# BlueNRG1 register map
Vendor: STMicroelectronics; Series: BlueNRG1; File version: 2.2.1
CPU: CM0 r0p0, little endian, no MPU, no FPU, 2 interrupt priority bits
Registers are 32-bit, read-write, reset 0x0 unless marked. A register's access mark holds for its fields unless they carry their own. Offsets are from the block's base; [hi:lo] are bit positions; 'fields as' and 'values as' point back to an identical list; <NAME> marks a mode.

## MFT1
Base 0x40D00000
Same registers: MFT2 0x40E00000
0x00 TNCNT1 16-bit — The Timer/Counter 1 register is a 16-bit RW register that is not altered by reset and thus contains random data upon power-up. Reading the register returns the current value of the Timer/Counter 1. TnCNT1 can only be written by the software when MFT is enabled (TnEN = 1). When MFT is disabled (TnEN = 0), write operations on TnCNT1 register are ignored.
0x04 TNCRA 16-bit — The Capture/Reload A register is a 16-bit RW register that is not affected by reset and thus contains random data upon power-up. The software may read the register at any time. However, the register can only be written by the software when MFT is enabled (TnEN = 1). When MFT is disabled (TnEN = 0), write operations on TnCRA register are ignored.
0x08 TNCRB 16-bit — The Capture/Reload B register is a 16-bit RW register that is not affected by reset and thus contains random data upon power-up. The software may read the register at any time. However, the register can only be written by the software when MFT is enabled (TnEN = 1). When MFT is disabled (TnEN = 0), write operations on TnCRB register are ignored.
0x0C TNCNT2 16-bit — The Timer/Counter 2 register is a 16-bit RW register that is not altered by reset and thus contains random data upon power-up. Reading the register returns the current value of the Timer/Counter 2. TnCNT2 can only be written by the software when MFT is enabled (TnEN = 1). When MFT is disabled (TnEN = 0), write operations on TnCNT2 register are ignored.
0x10 TNPRSC 8-bit — It contains the current value of the clock prescaler, which determines the timer clock prescaler ratio. The register value can be changed at any time. The timer clock is generated by dividing the system clock by TnPRSC + 1. Therefore, the maximum timer clock frequency is equal to the frequency of the system clock (TnPRSC = 0x00), and the minimum timer clock is the frequency of the system clock divided by 256 (TnPRSC = 0xFF).
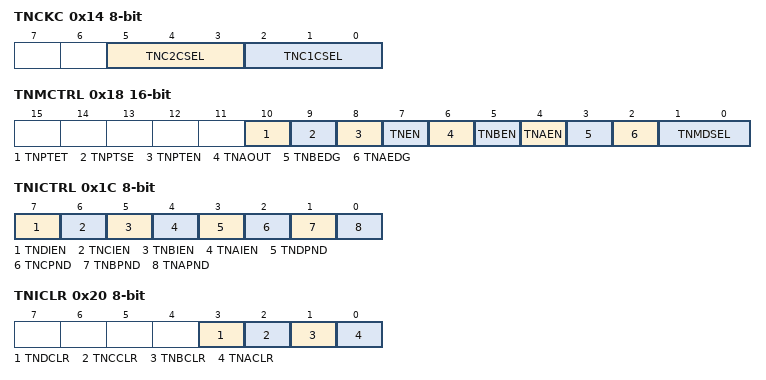
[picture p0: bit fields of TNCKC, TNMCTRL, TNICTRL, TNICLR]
0x14 TNCKC 8-bit — Clock unit control register
  [5:3] TNC2CSEL — Define the clock mode for Timer/Counter 2:<ul><li>000b: No clock (Timer/Counter 2 stopped).</li><li>001b: System clock with configurable prescaler (register TnPRSC).</li><li>010b: External event on TnB (mode 1 and 3 only).</li><li>011b: Pulse accumulate (mode 1 and 3 only).</li><li>100b: 16 MHz clock without prescaler (only when the system clock is 32 MHz).</li></ul>
    0=NO_CLOCK (No clock (Timer/Counter stopped)); 1=PRESCALED (System clock with configurable prescaler (register TnPRSC).); 2=EXTERNAL_EVENT (External event on TnB); 3=PULSE_ACCUMULATE; 4=LOW_SPEED_CLOCK (Not prescaled 16 MHz clock)
  [2:0] TNC1CSEL — Define the clock mode for Timer/Counter 1:<ul><li>000b: No clock (Timer/Counter 1 stopped).</li><li>001b: System clock with configurable prescaler (register TnPRSC).</li><li>010b: External event on TnB (mode 1 and 3 only).</li><li>011b: Pulse accumulate (mode 1 and 3 only).</li><li>100b: 16 MHz clock without prescaler (only when the system clock is 32 MHz).</li></ul>
    values as TNC2CSEL
0x18 TNMCTRL 16-bit — Timer mode control register
  [10] TNPTET — Tn Pulse-Train event trigger: if set (1) while operating in pulse-train mode (mode 1a) and the TnPTSE bit is set (1), pulse-train generation is triggered. When Timer/Counter 2 (TnCNT2) reaches its underflow condition, this bit is reset (0). If the TnPTSE bit is not set (0) while operating in mode 1a, the TnPTET bit cannot be written. <ul><li>0: No pulse-train event trigger occurred.</li><li>1: Pulse-train event trigger occurred (in mode 1a).</li></ul>
  [9] TNPTSE — Tn Pulse-Train software trigger enable: if set (1) while operating in PWM pulse-train mode (mode 1a), the pulse-train generation can only be triggered by setting the TnPTET to 1. If the TnPTSE bit is reset (0), pulses are generated only if a transition occurs on TnB. The bit has no effect while operating in any other modes than timer mode 1a:<ul><li>0: No effect.</li><li>1: Pulse-train generation trigger (in mode 1a)</li></ul>
  [8] TNPTEN — This bitfield enable the mode 1a. If set (1) while TnMDSEL is set to 00b, the Timer/Counter 1 operates in PWM pulse-train mode (mode 1a). The bit has no effect while TnMDSEL is set to any value other than 00b:<ul><li>0: Mode 1a not selected.</li><li>1: Mode 1a selected (if TnMDSEL = 00b).</li></ul>
  [7] TNEN — MFT is enabled if the bit is set (1), otherwise it is disabled. When MFT is disabled, all clocks to the counter unit are stopped, thus decreasing power consumption to a minimum. For that reason, the Timer/Counter registers (TnCNT1, TnCNT2), the Capture/Reload registers (TnCRA, TnCRB) and the interrupt-pending bits (TnXPND) cannot be written by software. Furthermore, the 8-bit clock prescaler and the interrupt-pending bits are reset and the TnA I/O pin becomes an input.
    0=MFTX_DISABLE; 1=MFTX_ENABLE
  [6] TNAOUT — It contains the value of the TnA when used as PWM output. The bit will be set and cleared by the hardware and thus reflects the status of TnA. The bit can be read or written by software at any time. If the hardware is attempting to toggle the bit at the same time that software writes to the bit, the software write will take precedence over the hardware update. The bit has no effect when TnA is used as an input or when the module is disabled:<ul><li>0: TnA pin is low.</li><li>1: TnA pin is high.</li></ul>
    0=LOW (TnA pin is low); 1=HIGH (TnA pin is high)
  [5] TNBEN — TnB Enable: If set (1) and while operating in dual-input capture mode (mode 2) or input capture and timer mode (mode 4), a transition on TnB will cause the corresponding Timer/Counter to be preset to 0xFFFF. In mode 2, TnCNT1 will be preset to 0xFFFF, while in mode 4, TnCNT2 is preset to 0xFFFF. The bit has no effect while operating in any other modes than mode 2 or mode 4:<ul><li>0: TnB input disable.</li><li>1: TnB input enable.</li></ul>
    0=TNB_IN_DISABLE (TNB input disable); 1=TNB_IN_ENABLE (TNB input enable)
  [4] TNAEN — Enables TnA to either function as a preset input or as a PWM output depending on the mode of operation. If the bit is set (1) while operating in the dual-input capture mode (mode 2), a transition on TnA causes TnCNT1 to be preset to 0xFFFF. In the remaining modes of operation, setting TnAEN enables TnA to function as a PWM output:<ul><li>0: TnA input disable.</li><li>1: TnA input enable.</li></ul>
    0=TNA_IN_DISABLE (TnA input disable); 1=TNA_IN_ENABLE (TnA input enable)
  [3] TNBEDG — Configure the TnB edge polarity for trigging an action:<ul><li>0: Input is sensitive to falling edges.</li><li>1: Input is sensitive to rising edges.</li></ul>
    0=FALLING_EDGE (Input is sensitive to falling edges); 1=RISING_EDGE (Input is sensitive to rising edges)
  [2] TNAEDG — Configure the TnA edge polarity for trigging an action:<ul><li>0: Input is sensitive to falling edges.</li><li>1: Input is sensitive to rising edges.</li></ul>
    values as TNBEDG
  [1:0] TNMDSEL — MFTX mode select:<ul><li>00b: Mode 1 or 1a: PWM mode and system timer or pulse train.</li><li>01b: Mode 2: Dual-input capture and system timer.</li><li>10b: Mode 3: Dual independent Timer/Counter.</li><li>11b: Mode 4: Single timer and single input capture.</li></ul>
    0=PWM (PWM mode and system timer or pulse train); 1=DUAL_INPUT_CAPTURE (Dual-input capture and system timer); 2=DUAL_INDEPENDENT (Dual independent Timer/Counter); 3=SINGLE (Single timer and single input capture)
0x1C TNICTRL 8-bit — Timer interrupt control register
  [7] TNDIEN — Timer interrupt D enable:<ul><li>0: Interrupt disabled.</li><li>1: Interrupt enabled.</li></ul>
  [6] TNCIEN — Timer interrupt C enable:<ul><li>0: Interrupt disabled.</li><li>1: Interrupt enabled.</li></ul>
  [5] TNBIEN — Timer interrupt B enable:<ul><li>0: Interrupt disabled.</li><li>1: Interrupt enabled.</li></ul>
  [4] TNAIEN — Timer interrupt A enable:<ul><li>0: Interrupt disabled.</li><li>1: Interrupt enabled.</li></ul>
  [3] TNDPND ro — Timer interrupt D pending:<ul><li>0: No interrupt source pending.</li><li>1: Interrupt source pending.</li></ul>
  [2] TNCPND ro — Timer interrupt C pending:<ul><li>0: No interrupt source pending.</li><li>1: Interrupt source pending.</li></ul>
  [1] TNBPND ro — Timer interrupt B pending:<ul><li>0: No interrupt source pending.</li><li>1: Interrupt source pending.</li></ul>
  [0] TNAPND ro — Timer interrupt A pending:<ul><li>0: No interrupt source pending.</li><li>1: Interrupt source pending.</li></ul>
0x20 TNICLR 8-bit wo — Timer interrupt clear register
  [3] TNDCLR — 1: clear the timer pending flag D.
  [2] TNCCLR — 1: clear the timer pending flag C.
  [1] TNBCLR — 1: clear the timer pending flag B.
  [0] TNACLR — 1: clear the timer pending flag A.
